# VPAC1_COMMON_0_PAR_VPAC_MSC_CFG_VP_LSE_CFG_VP register map
Vendor: Texas Instruments
Peripheral module from a debugger description file (folder J7_AHP).
Registers are 32-bit, read-write, reset 0x0 unless marked. A register's access mark holds for its fields unless they carry their own. Offsets are as the file gives them; lines under a group give offsets from that group; [hi:lo] are bit positions; {n}, {i} and the like mark numbered series; 'fields as' and 'values as' point back to an identical list; <NAME> marks a mode.

## VPAC1_COMMON_0_PAR_VPAC_MSC_CFG_VP_LSE_CFG_VP
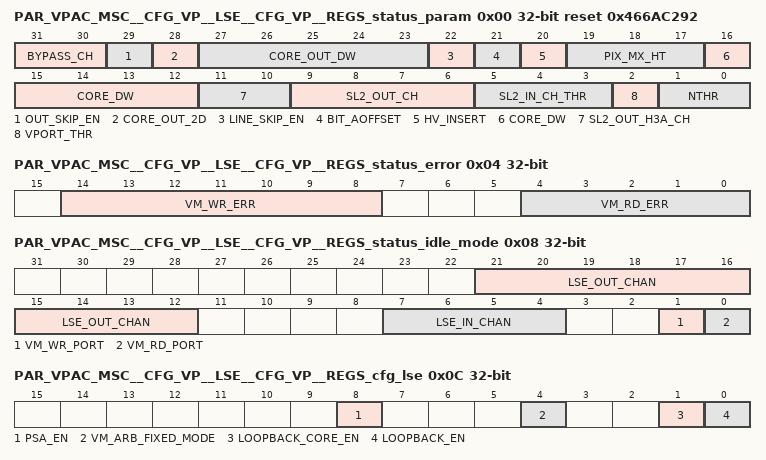
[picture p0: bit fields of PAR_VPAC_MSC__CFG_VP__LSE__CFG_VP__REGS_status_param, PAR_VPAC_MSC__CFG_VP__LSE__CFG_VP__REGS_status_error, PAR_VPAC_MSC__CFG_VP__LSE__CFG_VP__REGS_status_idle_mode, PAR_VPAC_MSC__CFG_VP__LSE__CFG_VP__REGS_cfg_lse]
0x00 PAR_VPAC_MSC__CFG_VP__LSE__CFG_VP__REGS_status_param ro reset 0x466AC292
  [31:30] BYPASS_CH — Number of available input channel selection for loopback mode
  [29] OUT_SKIP_EN — Output Auto-Skip Enable
  [28] CORE_OUT_2D — 1D or 2D output addressing mode(2D if 1)
  [27:23] CORE_OUT_DW — Core Output Channel Data Width
  [22] LINE_SKIP_EN — Source Line Inc by 2 Supported (if 1)
  [21] BIT_AOFFSET — Source nibble offset address Supported (if 1)
  [20] HV_INSERT — H/VBLANK Insertion Supported (if 1)
  [19:17] PIX_MX_HT — Core_Input Pixel Matrix Height
  [16:12] CORE_DW — Core Input Data Bus Width
  [11:10] SL2_OUT_H3A_CH — Number of SL2 H3A Output Channels
  [9:6] SL2_OUT_CH — Number of SL2 Output Channels
  [5:3] SL2_IN_CH_THR — Number of Input Channels per thread
  [2] VPORT_THR — Number of VPORT input enabled
  [1:0] NTHR — Number of threads supported
0x04 PAR_VPAC_MSC__CFG_VP__LSE__CFG_VP__REGS_status_error access not given
  [14:8] VM_WR_ERR — VBUSM I/F Last Write Error Status [14:11] Write Channel Number [10:8] VBUSM write error status (access R/W1TC)
  [4:0] VM_RD_ERR — VBUSM I/F Last Read Error Status [4:3] Read Channel Number [2:0] VBUSM read error status (access R/W1TC)
0x08 PAR_VPAC_MSC__CFG_VP__LSE__CFG_VP__REGS_status_idle_mode ro
  [21:12] LSE_OUT_CHAN — Output Channel[9:0] Status
  [7:4] LSE_IN_CHAN — Input Channel[3:0] Status
  [1] VM_WR_PORT — SL2 vbusm I/F Write Port Status
  [0] VM_RD_PORT — SL2 vbusm I/F Read Port Status
0x0C PAR_VPAC_MSC__CFG_VP__LSE__CFG_VP__REGS_cfg_lse
  [8] PSA_EN — Test mode Output Channel Signature Generation Enable 0: Disable (default) 1: Enable When enabled, LSE generates a unique CRC signature for each output channel's frame data at frame completion.
  [4] VM_ARB_FIXED_MODE — VBUSM Arbitration Fixed Mode select 0: Round-Robin Arbitration (default) 1: Fixed-mode Arbitration
  [1] LOOPBACK_CORE_EN — Functional path (data to HWA core) enable during loopback mode 0: Disable 1: Enable When enabled, the loopback-enabled input channel is used also for CORE data input. Otherwise, it is strictly used for the loopback path.
  [0] LOOPBACK_EN — LSE loopback mode enable 0: Disable 1: Enable When enabled, the second thread's input channel data (middle tap data) is looped back out to the last (#9) output channel.
0x13C PAR_VPAC_MSC__CFG_VP__LSE__CFG_VP__REGS_dst_common_cfg reset 0x8
  [5:0] ROUNDING_OFFSET — output channel rounding offset value. Default value to be considered 6'h08
0x140 PAR_VPAC_MSC__CFG_VP__LSE__CFG_VP__REGS_psa_signature ro
  [31:0] VALUE — 32-bit CRC signature value
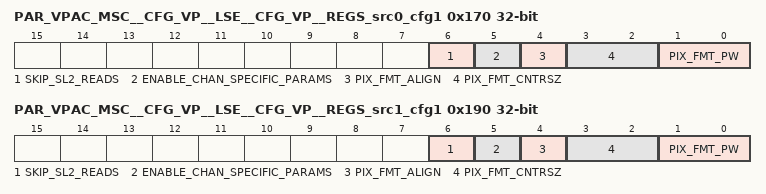
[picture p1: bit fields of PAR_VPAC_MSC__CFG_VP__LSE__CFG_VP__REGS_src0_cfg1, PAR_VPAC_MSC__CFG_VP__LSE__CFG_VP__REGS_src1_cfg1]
0x170 PAR_VPAC_MSC__CFG_VP__LSE__CFG_VP__REGS_src0_cfg1
  [6] SKIP_SL2_READS — When set, skips SL2 reads from the channel and channel0 read_data is redirected to the current channel
  [5] ENABLE_CHAN_SPECIFIC_PARAMS — Enables channel specific SRC_CFG and FRAME_SIZE parameters. 0 : Current channel config parameters are derived from chan0 MMR's. 1 : Current channel config parameters are derived from channel specific MMR's
  [4] PIX_FMT_ALIGN — Input Pixel Container Alignment 0: LSB-aligned 1: MSB-aligned
  [3:2] PIX_FMT_CNTRSZ — Input Pixel Container Size Sel 0: 8-bit 1: 12-bit 2: 16-bit 3: reserved Input pixel container size must be same or larger than input pixel width.
  [1:0] PIX_FMT_PW — Input Pixel Width Sel 0: 8-bit 1: 12-bit 2: 14-bit 3: 16-bit The width defines the bit-depth of the pixel data to be extracted from the pixel container.
0x174 PAR_VPAC_MSC__CFG_VP__LSE__CFG_VP__REGS_src0_frame_size1
  [12:0] WIDTH — SL2 - Source Buffer Width (number of pixels)
0x190 PAR_VPAC_MSC__CFG_VP__LSE__CFG_VP__REGS_src1_cfg1
  fields as PAR_VPAC_MSC__CFG_VP__LSE__CFG_VP__REGS_src0_cfg1
0x194 PAR_VPAC_MSC__CFG_VP__LSE__CFG_VP__REGS_src1_frame_size1
  [12:0] WIDTH — SL2 - Source Buffer Width (number of pixels)
0x1E0 PAR_VPAC_MSC__CFG_VP__LSE__CFG_VP__REGS_dbg ro
  [31:0] STATUS — Debug status
